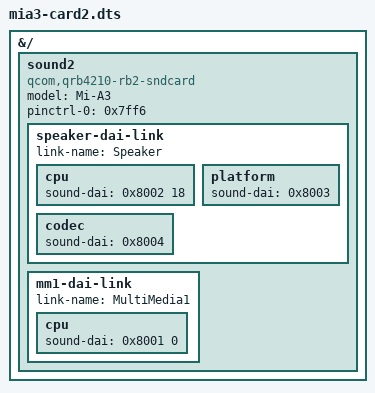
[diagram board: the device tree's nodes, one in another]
/dts-v1/;
/plugin/;
/* Same card as mia3-card.dts, links listed speaker-first: the overlay attaches child nodes in reverse,
 * so MultiMedia1 (q6asm-dai) ends up first and its widgets exist before q6routing adds its routes. */
&{/} {
	sound2 {
		compatible = "qcom,qrb4210-rb2-sndcard";
		model = "Mi-A3";
		pinctrl-0 = <0x7ff6>;
		pinctrl-names = "default";
		speaker-dai-link {
			link-name = "Speaker";
			cpu { sound-dai = <0x8002 18>; };
			platform { sound-dai = <0x8003>; };
			codec { sound-dai = <0x8004>; };
		};
		mm1-dai-link {
			link-name = "MultiMedia1";
			cpu { sound-dai = <0x8001 0>; };
		};
	};
};
